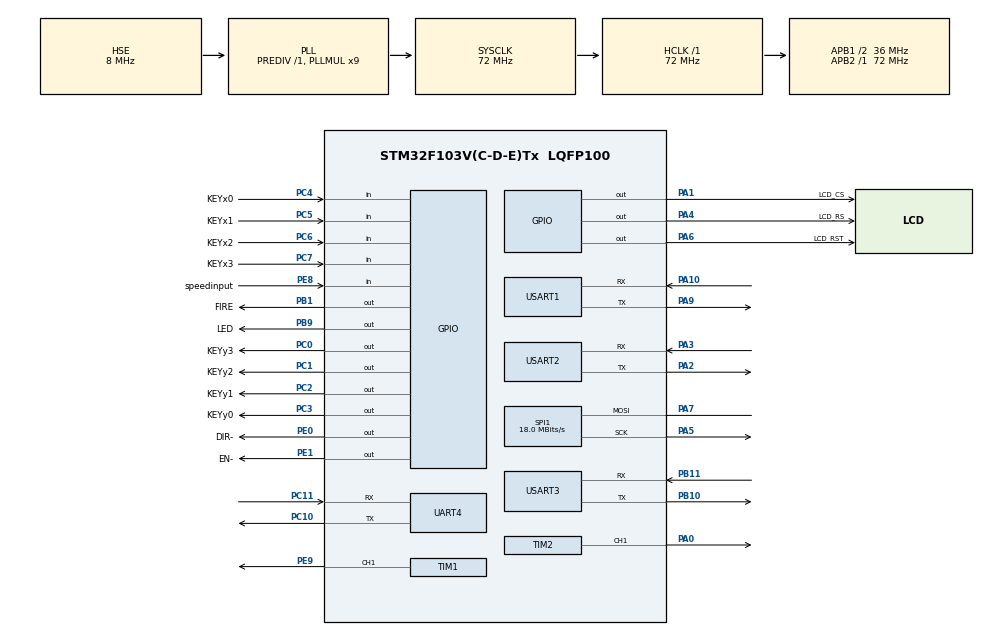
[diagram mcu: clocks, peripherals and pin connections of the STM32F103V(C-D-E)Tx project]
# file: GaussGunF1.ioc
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Mcu.Family=STM32F1
Mcu.Name=STM32F103V(C-D-E)Tx
Mcu.Package=LQFP100
NVIC.PriorityGroup=NVIC_PRIORITYGROUP_4
NVIC.TIM2_IRQn=true\:0\:0\:false\:false\:true\:true\:true
NVIC.USART1_IRQn=true\:1\:0\:true\:false\:true\:true\:true
NVIC.USART2_IRQn=true\:2\:0\:true\:false\:true\:true\:true
NVIC.USART3_IRQn=true\:3\:0\:true\:false\:true\:true\:true
OSC_IN.Mode=HSE-External-Oscillator
OSC_IN.Signal=RCC_OSC_IN
OSC_OUT.Mode=HSE-External-Oscillator
OSC_OUT.Signal=RCC_OSC_OUT
PA0-WKUP.Signal=S_TIM2_CH1_ETR
PA1.GPIO_Label=LCD_CS
PA1.GPIO_Speed=GPIO_SPEED_FREQ_HIGH
PA1.PinState=GPIO_PIN_SET
PA1.Signal=GPIO_Output
PA10.Mode=Asynchronous
PA10.Signal=USART1_RX
PA13.Mode=Serial_Wire
PA13.Signal=SYS_JTMS-SWDIO
PA14.Mode=Serial_Wire
PA14.Signal=SYS_JTCK-SWCLK
PA2.Mode=Asynchronous
PA2.Signal=USART2_TX
PA3.Mode=Asynchronous
PA3.Signal=USART2_RX
PA4.GPIO_Label=LCD_RS
PA4.Signal=GPIO_Output
PA5.Mode=Simplex_Bidirectional_Master
PA5.Signal=SPI1_SCK
PA6.GPIO_Label=LCD_RST
PA6.GPIO_Speed=GPIO_SPEED_FREQ_HIGH
PA6.PinState=GPIO_PIN_SET
PA6.Signal=GPIO_Output
PA7.Mode=Simplex_Bidirectional_Master
PA7.Signal=SPI1_MOSI
PA9.Mode=Asynchronous
PA9.Signal=USART1_TX
PB1.GPIO_Label=FIRE
PB1.GPIO_Speed=GPIO_SPEED_FREQ_HIGH
PB1.PinState=GPIO_PIN_SET
PB1.Signal=GPIO_Output
PB10.Mode=Asynchronous
PB10.Signal=USART3_TX
PB11.Mode=Asynchronous
PB11.Signal=USART3_RX
PB9.GPIO_Label=LED
PB9.GPIO_ModeDefaultOutputPP=GPIO_MODE_OUTPUT_OD
PB9.PinState=GPIO_PIN_SET
PB9.Signal=GPIO_Output
PC0.GPIO_Label=KEYy3
PC0.Signal=GPIO_Output
PC1.GPIO_Label=KEYy2
PC1.Signal=GPIO_Output
PC10.Mode=Asynchronous
PC10.Signal=UART4_TX
PC11.Mode=Asynchronous
PC11.Signal=UART4_RX
PC14-OSC32_IN.Mode=LSE-External-Oscillator
PC14-OSC32_IN.Signal=RCC_OSC32_IN
PC15-OSC32_OUT.Mode=LSE-External-Oscillator
PC15-OSC32_OUT.Signal=RCC_OSC32_OUT
PC2.GPIO_Label=KEYy1
PC2.Signal=GPIO_Output
PC3.GPIO_Label=KEYy0
PC3.Signal=GPIO_Output
PC4.GPIO_Label=KEYx0
PC4.GPIO_PuPd=GPIO_PULLUP
PC4.Signal=GPIO_Input
PC5.GPIO_Label=KEYx1
PC5.GPIO_PuPd=GPIO_PULLUP
PC5.Signal=GPIO_Input
PC6.GPIO_Label=KEYx2
PC6.GPIO_PuPd=GPIO_PULLUP
PC6.Signal=GPIO_Input
PC7.GPIO_Label=KEYx3
PC7.GPIO_PuPd=GPIO_PULLUP
PC7.Signal=GPIO_Input
PE0.GPIO_Label=DIR-
PE0.GPIO_Speed=GPIO_SPEED_FREQ_HIGH
PE0.PinState=GPIO_PIN_SET
PE0.Signal=GPIO_Output
PE1.GPIO_Label=EN-
PE1.GPIO_Speed=GPIO_SPEED_FREQ_HIGH
PE1.Signal=GPIO_Output
PE8.GPIO_Label=speedinput
PE8.Signal=GPIO_Input
PE9.Signal=S_TIM1_CH1
ProjectManager.HeapSize=0x200
ProjectManager.StackSize=0x400
ProjectManager.TargetToolchain=MDK-ARM V5
RCC.AHBFreq_Value=72000000
RCC.APB1CLKDivider=RCC_HCLK_DIV2
RCC.APB1Freq_Value=36000000
RCC.APB1TimFreq_Value=72000000
RCC.APB2Freq_Value=72000000
RCC.APB2TimFreq_Value=72000000
RCC.HCLKFreq_Value=72000000
RCC.PLLMUL=RCC_PLL_MUL9
RCC.PLLSourceVirtual=RCC_PLLSOURCE_HSE
RCC.SYSCLKFreq_VALUE=72000000
RCC.SYSCLKSource=RCC_SYSCLKSOURCE_PLLCLK
RCC.USBFreq_Value=72000000
SH.S_TIM1_CH1.0=TIM1_CH1,PWM Generation1 CH1
SH.S_TIM2_CH1_ETR.0=TIM2_CH1,PWM Generation1 CH1
SPI1.BaudRatePrescaler=SPI_BAUDRATEPRESCALER_4
SPI1.CalculateBaudRate=18.0 MBits/s
SPI1.Direction=SPI_DIRECTION_1LINE
SPI1.Mode=SPI_MODE_MASTER
SPI1.VirtualType=VM_MASTER
TIM1.Channel-PWM\ Generation1\ CH1=TIM_CHANNEL_1
TIM1.Period=20000
TIM1.Prescaler=71
TIM1.Pulse-PWM\ Generation1\ CH1=1450
TIM2.Channel-PWM\ Generation1\ CH1=TIM_CHANNEL_1
TIM2.Period=999
TIM2.Prescaler=71
TIM2.Pulse-PWM\ Generation1\ CH1=0
TIM3.Period=1000
TIM3.Prescaler=71
TIM4.Period=65535
TIM4.Prescaler=71
TIM5.Period=65535
TIM5.Prescaler=71
UART4.VirtualMode=Asynchronous
USART1.VirtualMode=VM_ASYNC
USART2.VirtualMode=VM_ASYNC
USART3.VirtualMode=VM_ASYNC
VP_TIM1_VS_ClockSourceINT.Mode=Internal
VP_TIM2_VS_ClockSourceINT.Mode=Internal
VP_TIM3_VS_ClockSourceINT.Mode=Internal
VP_TIM4_VS_ClockSourceINT.Mode=Internal
VP_TIM5_VS_ClockSourceINT.Mode=Internal
board=custom

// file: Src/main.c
/* USER CODE BEGIN Header */
/**
  ******************************************************************************
  * @file           : main.c
  * @brief          : Main program body
  ******************************************************************************
  * @attention
  *
  * <h2><center>&copy; Copyright (c) 2019 STMicroelectronics.
  * All rights reserved.</center></h2>
  *
  * This software component is licensed by ST under BSD 3-Clause license,
  * the "License"; You may not use this file except in compliance with the
  * License. You may obtain a copy of the License at:
  *                        opensource.org/licenses/BSD-3-Clause
  *
  ******************************************************************************
  */
/* USER CODE END Header */

#include "main.h"
#include "spi.h"
#include "tim.h"
#include "usart.h"
#include "gpio.h"

/* USER CODE BEGIN Includes */
#include "stdio.h"
#include "User_main.h"
/* USER CODE END Includes */

void SystemClock_Config(void);

int main(void)
{

  /* MCU Configuration--------------------------------------------------------*/

  /* Reset of all peripherals, Initializes the Flash interface and the Systick. */
  HAL_Init();

  /* Configure the system clock */
  SystemClock_Config();

  /* Initialize all configured peripherals */
  MX_GPIO_Init();
  MX_SPI1_Init();
  MX_TIM3_Init();
  MX_USART1_UART_Init();
  MX_USART2_UART_Init();
  MX_USART3_UART_Init();
  MX_TIM5_Init();
  MX_TIM1_Init();
  MX_TIM2_Init();
  MX_TIM4_Init();
  MX_UART4_Init();
  /* USER CODE BEGIN 2 */
	HAL_NVIC_DisableIRQ(EXTI9_5_IRQn);
  /* USER CODE END 2 */

  /* Infinite loop */
  /* USER CODE BEGIN WHILE */
  while (1)
  {
		User_main();
    /* USER CODE END WHILE */

  }
}

void SystemClock_Config(void)
{
  RCC_OscInitTypeDef RCC_OscInitStruct = {0};
  RCC_ClkInitTypeDef RCC_ClkInitStruct = {0};

  /** Initializes the CPU, AHB and APB busses clocks
  */
  RCC_OscInitStruct.OscillatorType = RCC_OSCILLATORTYPE_HSE;
  RCC_OscInitStruct.HSEState = RCC_HSE_ON;
  RCC_OscInitStruct.HSEPredivValue = RCC_HSE_PREDIV_DIV1;
  RCC_OscInitStruct.HSIState = RCC_HSI_ON;
  RCC_OscInitStruct.PLL.PLLState = RCC_PLL_ON;
  RCC_OscInitStruct.PLL.PLLSource = RCC_PLLSOURCE_HSE;
  RCC_OscInitStruct.PLL.PLLMUL = RCC_PLL_MUL9;
  if (HAL_RCC_OscConfig(&RCC_OscInitStruct) != HAL_OK)
  {
    Error_Handler();
  }
  /** Initializes the CPU, AHB and APB busses clocks
  */
  RCC_ClkInitStruct.ClockType = RCC_CLOCKTYPE_HCLK|RCC_CLOCKTYPE_SYSCLK
                              |RCC_CLOCKTYPE_PCLK1|RCC_CLOCKTYPE_PCLK2;
  RCC_ClkInitStruct.SYSCLKSource = RCC_SYSCLKSOURCE_PLLCLK;
  RCC_ClkInitStruct.AHBCLKDivider = RCC_SYSCLK_DIV1;
  RCC_ClkInitStruct.APB1CLKDivider = RCC_HCLK_DIV2;
  RCC_ClkInitStruct.APB2CLKDivider = RCC_HCLK_DIV1;

  if (HAL_RCC_ClockConfig(&RCC_ClkInitStruct, FLASH_LATENCY_2) != HAL_OK)
  {
    Error_Handler();
  }
}

void Error_Handler(void)
{
}

/************************ (C) COPYRIGHT STMicroelectronics *****END OF FILE****/
